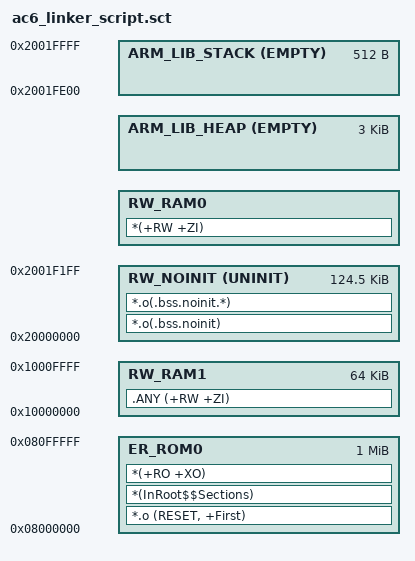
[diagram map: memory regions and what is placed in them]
# 1 "/Users/oledonnermeyer/Documents/coding/mc-praktikum/RTE/Device/STM32F407VGTx/ac6_linker_script.sct.src"
# 1 "<built-in>" 1
# 1 "<built-in>" 3
# 400 "<built-in>" 3
# 1 "<command line>" 1
# 1 "<built-in>" 2
# 1 "/Users/oledonnermeyer/Documents/coding/mc-praktikum/RTE/Device/STM32F407VGTx/regions_STM32F407VGTx.h" 1
# 2 "<built-in>" 2
# 1 "/Users/oledonnermeyer/Documents/coding/mc-praktikum/RTE/Device/STM32F407VGTx/ac6_linker_script.sct.src" 2
# 32 "/Users/oledonnermeyer/Documents/coding/mc-praktikum/RTE/Device/STM32F407VGTx/ac6_linker_script.sct.src"
LR_ROM0 0x08000000 0x00100000 {

  ER_ROM0 0x08000000 0x00100000 {
    *.o (RESET, +First)
    *(InRoot$$Sections)
    *(+RO +XO)
  }







  RW_NOINIT 0x20000000 UNINIT (0x00020000 - 0x00000C00 - 0x00000200 - 0) {
    *.o(.bss.noinit)
    *.o(.bss.noinit.*)
  }

  RW_RAM0 AlignExpr(+0, 8) (0x00020000 - 0x00000C00 - 0x00000200 - 0 - AlignExpr(ImageLength(RW_NOINIT), 8)) {
    *(+RW +ZI)
  }


  ARM_LIB_HEAP (AlignExpr(+0, 8)) EMPTY 0x00000C00 { ; Reserve empty region for heap
  }


  ARM_LIB_STACK (0x20000000 + 0x00020000 - 0) EMPTY -0x00000200 { ; Reserve empty region for stack
  }







  RW_RAM1 0x10000000 0x00010000 {
   .ANY (+RW +ZI)
  }
# 85 "/Users/oledonnermeyer/Documents/coding/mc-praktikum/RTE/Device/STM32F407VGTx/ac6_linker_script.sct.src"
}
